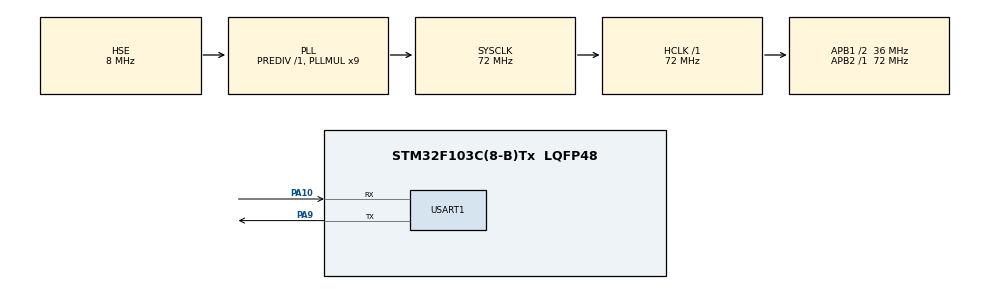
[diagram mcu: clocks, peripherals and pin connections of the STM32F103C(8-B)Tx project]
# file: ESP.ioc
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Mcu.Family=STM32F1
Mcu.Name=STM32F103C(8-B)Tx
Mcu.Package=LQFP48
NVIC.PriorityGroup=NVIC_PRIORITYGROUP_4
PA10.Mode=Asynchronous
PA10.Signal=USART1_RX
PA13.Mode=Serial_Wire
PA13.Signal=SYS_JTMS-SWDIO
PA14.Mode=Serial_Wire
PA14.Signal=SYS_JTCK-SWCLK
PA9.Mode=Asynchronous
PA9.Signal=USART1_TX
PC14-OSC32_IN.Mode=LSE-External-Oscillator
PC14-OSC32_IN.Signal=RCC_OSC32_IN
PC15-OSC32_OUT.Mode=LSE-External-Oscillator
PC15-OSC32_OUT.Signal=RCC_OSC32_OUT
PD0-OSC_IN.Mode=HSE-External-Oscillator
PD0-OSC_IN.Signal=RCC_OSC_IN
PD1-OSC_OUT.Mode=HSE-External-Oscillator
PD1-OSC_OUT.Signal=RCC_OSC_OUT
ProjectManager.HeapSize=0x200
ProjectManager.StackSize=0x400
ProjectManager.TargetToolchain=STM32CubeIDE
RCC.AHBFreq_Value=72000000
RCC.APB1CLKDivider=RCC_HCLK_DIV2
RCC.APB1Freq_Value=36000000
RCC.APB1TimFreq_Value=72000000
RCC.APB2Freq_Value=72000000
RCC.APB2TimFreq_Value=72000000
RCC.HCLKFreq_Value=72000000
RCC.PLLMUL=RCC_PLL_MUL9
RCC.PLLSourceVirtual=RCC_PLLSOURCE_HSE
RCC.SYSCLKFreq_VALUE=72000000
RCC.SYSCLKSource=RCC_SYSCLKSOURCE_PLLCLK
RCC.USBFreq_Value=72000000
USART1.VirtualMode=VM_ASYNC
VP_TIM1_VS_ClockSourceINT.Mode=Internal
board=custom

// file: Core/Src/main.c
/* USER CODE BEGIN Header */
/**
  ******************************************************************************
  * @file           : main.c
  * @brief          : Main program body
  ******************************************************************************
  * @attention
  *
  * <h2><center>&copy; Copyright (c) 2022 STMicroelectronics.
  * All rights reserved.</center></h2>
  *
  * This software component is licensed by ST under BSD 3-Clause license,
  * the "License"; You may not use this file except in compliance with the
  * License. You may obtain a copy of the License at:
  *                        opensource.org/licenses/BSD-3-Clause
  *
  ******************************************************************************
  */
/* USER CODE END Header */

#include "main.h"

/* USER CODE BEGIN Includes */
#include <stdio.h>
#include <string.h>
/* USER CODE END Includes */

TIM_HandleTypeDef htim1;

UART_HandleTypeDef huart1;

void SystemClock_Config(void);
static void MX_GPIO_Init(void);
static void MX_TIM1_Init(void);
static void MX_USART1_UART_Init(void);

/* USER CODE BEGIN 0 */
const char AT[6]="AT\r\n";
const char CWMODE[20]="AT+CWMODE=1\r\n";
const char CWJAP[40]="AT+CWJAP=\"TeleCentro-fa12\",\"35124076\"\r\n";
const char RESTORE[15]="AT+RESTORE\r\n";
//const char* HTTPCLIENT="AT+HTTPCLIENT=3,0,\"https://fast-savannah-92289.herokuapp.com//app/v1/temperatura\",\"https://fast-savannah-92289.herokuapp.com/\",\"/app/v1/temperatura\",1,\"temp=\"value\"\r\n";

const char* HTTPCLIENT="AT+HTTPCLIENT=1,0,\"http://httpbin.org/get\",\"httpbin.org\",\"/get\",1\r\n";
//const char* HTTPCLIENT="AT+HTTPGETSIZE=\"https://www.google.com.ar\"\r\n";
//const char HTTPCLIENT[150]="AT+HTTPCLIENT=3,0,\"http://fast-savannah-92289.herokuapp.com//app/v1/temperatura\",,,1,\"temp=\"value\"\r\n";
//"https://fast-savannah-92289.herokuapp.com//app/v1/temperatura"

//const char AT[6]="AT";
//const char AT[6]="AT";
const char* ssid = "TeleCentro-fa12";
const char* password =  "35124076";

/* USER CODE END 0 */

int main(void)
{

  /* MCU Configuration--------------------------------------------------------*/

  /* Reset of all peripherals, Initializes the Flash interface and the Systick. */
  HAL_Init();

  /* Configure the system clock */
  SystemClock_Config();

  /* Initialize all configured peripherals */
  MX_GPIO_Init();
  MX_TIM1_Init();
  MX_USART1_UART_Init();
  /* USER CODE BEGIN 2 */
  HAL_TIM_Base_Start(&htim1);
  /* USER CODE END 2 */

  /* Infinite loop */
  /* USER CODE BEGIN WHILE */
  HAL_UART_Transmit(&huart1, (uint8_t*)RESTORE, strlen(RESTORE), 300);
  HAL_Delay(1000);

  HAL_UART_Transmit(&huart1, (uint8_t*)CWMODE, strlen(CWMODE), 300);
  HAL_Delay(1000);

  HAL_UART_Transmit(&huart1, (uint8_t*)CWJAP, strlen(CWJAP), 300);
  HAL_Delay(10000);

  while (1)
  {
    /* USER CODE END WHILE */

    /* USER CODE BEGIN 3 */
//	  HAL_UART_Transmit(&huart1, (uint8_t*)AT, strlen(AT), 300);
//	  HAL_Delay(1000);
//
//	  HAL_UART_Transmit(&huart1, (uint8_t*)CWMODE, strlen(CWMODE), 300);
//	  HAL_Delay(1000);
//
//	  HAL_UART_Transmit(&huart1, (uint8_t*)CWJAP, strlen(CWJAP), 300);
//	  HAL_Delay(1000);
//
//	  HAL_UART_Transmit(&huart1, (uint8_t*)CIPMUX, strlen(CIPMUX), 300);
//	  HAL_Delay(1000);
//
//	  HAL_UART_Transmit(&huart1, (uint8_t*)CIPSERVER, strlen(CIPSERVER), 300);
//	  HAL_Delay(1000);

	  HAL_UART_Transmit(&huart1, (uint8_t*)HTTPCLIENT, strlen(HTTPCLIENT), 300);
	  HAL_Delay(1000);

  }
  /* USER CODE END 3 */
}

void SystemClock_Config(void)
{
  RCC_OscInitTypeDef RCC_OscInitStruct = {0};
  RCC_ClkInitTypeDef RCC_ClkInitStruct = {0};

  /** Initializes the CPU, AHB and APB busses clocks
  */
  RCC_OscInitStruct.OscillatorType = RCC_OSCILLATORTYPE_HSE;
  RCC_OscInitStruct.HSEState = RCC_HSE_ON;
  RCC_OscInitStruct.HSEPredivValue = RCC_HSE_PREDIV_DIV1;
  RCC_OscInitStruct.HSIState = RCC_HSI_ON;
  RCC_OscInitStruct.PLL.PLLState = RCC_PLL_ON;
  RCC_OscInitStruct.PLL.PLLSource = RCC_PLLSOURCE_HSE;
  RCC_OscInitStruct.PLL.PLLMUL = RCC_PLL_MUL9;
  if (HAL_RCC_OscConfig(&RCC_OscInitStruct) != HAL_OK)
  {
    Error_Handler();
  }
  /** Initializes the CPU, AHB and APB busses clocks
  */
  RCC_ClkInitStruct.ClockType = RCC_CLOCKTYPE_HCLK|RCC_CLOCKTYPE_SYSCLK
                              |RCC_CLOCKTYPE_PCLK1|RCC_CLOCKTYPE_PCLK2;
  RCC_ClkInitStruct.SYSCLKSource = RCC_SYSCLKSOURCE_PLLCLK;
  RCC_ClkInitStruct.AHBCLKDivider = RCC_SYSCLK_DIV1;
  RCC_ClkInitStruct.APB1CLKDivider = RCC_HCLK_DIV2;
  RCC_ClkInitStruct.APB2CLKDivider = RCC_HCLK_DIV1;

  if (HAL_RCC_ClockConfig(&RCC_ClkInitStruct, FLASH_LATENCY_2) != HAL_OK)
  {
    Error_Handler();
  }
}

static void MX_TIM1_Init(void)
{

  TIM_ClockConfigTypeDef sClockSourceConfig = {0};
  TIM_MasterConfigTypeDef sMasterConfig = {0};

  htim1.Instance = TIM1;
  htim1.Init.Prescaler = 0;
  htim1.Init.CounterMode = TIM_COUNTERMODE_UP;
  htim1.Init.Period = 0;
  htim1.Init.ClockDivision = TIM_CLOCKDIVISION_DIV1;
  htim1.Init.RepetitionCounter = 0;
  htim1.Init.AutoReloadPreload = TIM_AUTORELOAD_PRELOAD_DISABLE;
  if (HAL_TIM_Base_Init(&htim1) != HAL_OK)
  {
    Error_Handler();
  }
  sClockSourceConfig.ClockSource = TIM_CLOCKSOURCE_INTERNAL;
  if (HAL_TIM_ConfigClockSource(&htim1, &sClockSourceConfig) != HAL_OK)
  {
    Error_Handler();
  }
  sMasterConfig.MasterOutputTrigger = TIM_TRGO_RESET;
  sMasterConfig.MasterSlaveMode = TIM_MASTERSLAVEMODE_DISABLE;
  if (HAL_TIMEx_MasterConfigSynchronization(&htim1, &sMasterConfig) != HAL_OK)
  {
    Error_Handler();
  }

}

static void MX_USART1_UART_Init(void)
{

  huart1.Instance = USART1;
  huart1.Init.BaudRate = 115200;
  huart1.Init.WordLength = UART_WORDLENGTH_8B;
  huart1.Init.StopBits = UART_STOPBITS_1;
  huart1.Init.Parity = UART_PARITY_NONE;
  huart1.Init.Mode = UART_MODE_TX_RX;
  huart1.Init.HwFlowCtl = UART_HWCONTROL_NONE;
  huart1.Init.OverSampling = UART_OVERSAMPLING_16;
  if (HAL_UART_Init(&huart1) != HAL_OK)
  {
    Error_Handler();
  }

}

static void MX_GPIO_Init(void)
{

  /* GPIO Ports Clock Enable */
  __HAL_RCC_GPIOC_CLK_ENABLE();
  __HAL_RCC_GPIOD_CLK_ENABLE();
  __HAL_RCC_GPIOA_CLK_ENABLE();

}

void Error_Handler(void)
{
}

/************************ (C) COPYRIGHT STMicroelectronics *****END OF FILE****/
